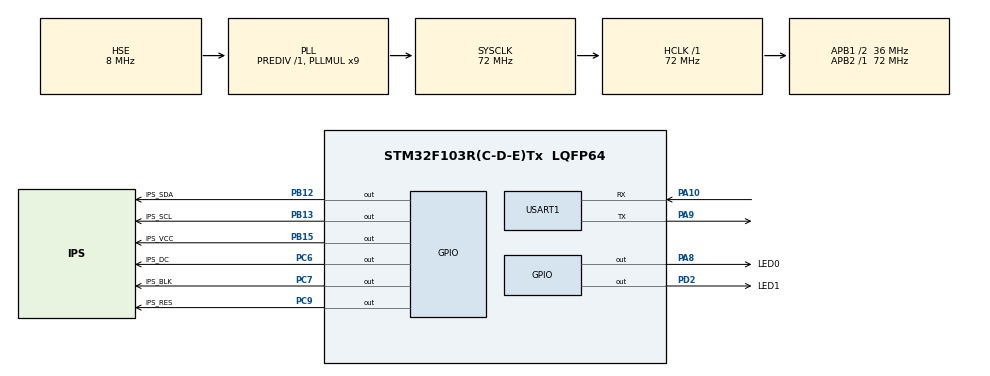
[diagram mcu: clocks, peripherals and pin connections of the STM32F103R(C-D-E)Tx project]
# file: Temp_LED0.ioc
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Mcu.Family=STM32F1
Mcu.Name=STM32F103R(C-D-E)Tx
Mcu.Package=LQFP64
NVIC.PriorityGroup=NVIC_PRIORITYGROUP_4
NVIC.USART1_IRQn=true\:2\:0\:true\:false\:true\:true\:true
PA10.Mode=Asynchronous
PA10.Signal=USART1_RX
PA13.Mode=Serial_Wire
PA13.Signal=SYS_JTMS-SWDIO
PA14.Mode=Serial_Wire
PA14.Signal=SYS_JTCK-SWCLK
PA8.GPIO_Label=LED0
PA8.GPIO_ModeDefaultOutputPP=GPIO_MODE_OUTPUT_PP
PA8.GPIO_PuPd=GPIO_PULLUP
PA8.GPIO_Speed=GPIO_SPEED_FREQ_MEDIUM
PA8.PinState=GPIO_PIN_SET
PA8.Signal=GPIO_Output
PA9.Mode=Asynchronous
PA9.Signal=USART1_TX
PB12.GPIO_Label=IPS_SDA
PB12.GPIO_ModeDefaultOutputPP=GPIO_MODE_OUTPUT_PP
PB12.GPIO_PuPd=GPIO_PULLUP
PB12.GPIO_Speed=GPIO_SPEED_FREQ_HIGH
PB12.PinState=GPIO_PIN_SET
PB12.Signal=GPIO_Output
PB13.GPIO_Label=IPS_SCL
PB13.GPIO_PuPd=GPIO_PULLUP
PB13.GPIO_Speed=GPIO_SPEED_FREQ_HIGH
PB13.PinState=GPIO_PIN_SET
PB13.Signal=GPIO_Output
PB15.GPIO_Label=IPS_VCC
PB15.GPIO_ModeDefaultOutputPP=GPIO_MODE_OUTPUT_PP
PB15.GPIO_PuPd=GPIO_PULLUP
PB15.GPIO_Speed=GPIO_SPEED_FREQ_HIGH
PB15.PinState=GPIO_PIN_SET
PB15.Signal=GPIO_Output
PC14-OSC32_IN.Mode=LSE-External-Oscillator
PC14-OSC32_IN.Signal=RCC_OSC32_IN
PC15-OSC32_OUT.Mode=LSE-External-Oscillator
PC15-OSC32_OUT.Signal=RCC_OSC32_OUT
PC6.GPIO_Label=IPS_DC
PC6.GPIO_PuPd=GPIO_PULLUP
PC6.GPIO_Speed=GPIO_SPEED_FREQ_HIGH
PC6.PinState=GPIO_PIN_SET
PC6.Signal=GPIO_Output
PC7.GPIO_Label=IPS_BLK
PC7.GPIO_ModeDefaultOutputPP=GPIO_MODE_OUTPUT_PP
PC7.GPIO_PuPd=GPIO_PULLUP
PC7.GPIO_Speed=GPIO_SPEED_FREQ_HIGH
PC7.PinState=GPIO_PIN_SET
PC7.Signal=GPIO_Output
PC9.GPIO_Label=IPS_RES
PC9.GPIO_ModeDefaultOutputPP=GPIO_MODE_OUTPUT_PP
PC9.GPIO_PuPd=GPIO_PULLUP
PC9.GPIO_Speed=GPIO_SPEED_FREQ_HIGH
PC9.PinState=GPIO_PIN_SET
PC9.Signal=GPIO_Output
PD0-OSC_IN.Mode=HSE-External-Oscillator
PD0-OSC_IN.Signal=RCC_OSC_IN
PD1-OSC_OUT.Mode=HSE-External-Oscillator
PD1-OSC_OUT.Signal=RCC_OSC_OUT
PD2.GPIO_Label=LED1
PD2.GPIO_ModeDefaultOutputPP=GPIO_MODE_OUTPUT_PP
PD2.GPIO_PuPd=GPIO_PULLUP
PD2.GPIO_Speed=GPIO_SPEED_FREQ_HIGH
PD2.PinState=GPIO_PIN_SET
PD2.Signal=GPIO_Output
ProjectManager.HeapSize=0x200
ProjectManager.StackSize=0x400
ProjectManager.TargetToolchain=MDK-ARM V5
RCC.AHBFreq_Value=72000000
RCC.APB1CLKDivider=RCC_HCLK_DIV2
RCC.APB1Freq_Value=36000000
RCC.APB1TimFreq_Value=72000000
RCC.APB2Freq_Value=72000000
RCC.APB2TimFreq_Value=72000000
RCC.HCLKFreq_Value=72000000
RCC.PLLMUL=RCC_PLL_MUL9
RCC.PLLSourceVirtual=RCC_PLLSOURCE_HSE
RCC.SYSCLKFreq_VALUE=72000000
RCC.SYSCLKSource=RCC_SYSCLKSOURCE_PLLCLK
RCC.USBFreq_Value=72000000
USART1.VirtualMode=VM_ASYNC
board=custom

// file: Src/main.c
/* USER CODE BEGIN Header */
/**
  ******************************************************************************
  * @file           : main.c
  * @brief          : Main program body
  ******************************************************************************
  * @attention
  *
  * <h2><center>&copy; Copyright (c) 2019 STMicroelectronics.
  * All rights reserved.</center></h2>
  *
  * This software component is licensed by ST under BSD 3-Clause license,
  * the "License"; You may not use this file except in compliance with the
  * License. You may obtain a copy of the License at:
  *                        opensource.org/licenses/BSD-3-Clause
  *
  ******************************************************************************
  */
/* USER CODE END Header */

#include "main.h"
#include "usart.h"
#include "gpio.h"

/* USER CODE BEGIN Includes */
#include "lcd.h"
#include "SEGGER_RTT.h"
#include "SEGGER_RTT_Conf.h"
/* USER CODE END Includes */

void SystemClock_Config(void);

int main(void)
{
  /* USER CODE BEGIN 1 */
//	uint8_t temp[] = "study cube for stm32f103 \r\n";
//	uint8_t temp_lenth = sizeof temp;

	u8 x = 0, y = 0;
  /* USER CODE END 1 */

  /* MCU Configuration--------------------------------------------------------*/

  /* Reset of all peripherals, Initializes the Flash interface and the Systick. */
  HAL_Init();

  /* USER CODE BEGIN Init */

  /* Jlink RTT Viewer 初始化 */
  SEGGER_RTT_Init();

  /* IPS屏初始化 */
  Lcd_Init();
  LCD_Clear(BLACK);
  BACK_COLOR = BLACK;

  /* USER CODE END Init */

  /* Configure the system clock */
  SystemClock_Config();

  /* Initialize all configured peripherals */
  MX_GPIO_Init();
  MX_USART1_UART_Init();

  /* Infinite loop */
  /* USER CODE BEGIN WHILE */
  while (1)
  {
	  /* IO口操作 */
// 	  HAL_GPIO_TogglePin(LED0_GPIO_Port, LED0_Pin);
// 	  HAL_GPIO_TogglePin(LED1_GPIO_Port, LED1_Pin);

	  /* 串口打印日志 */
//	  HAL_UART_Transmit(&huart1, temp, temp_lenth, 100);

	  /* IPS屏 */
	  /* 字体移动 */
// 	  for (y = 0; y < 220; y = y + 3)
// 	  {
// 		  LCD_ShowString(0, y, "Study STM32F103:", GREEN);
// 	  }
// 	  LCD_ShowString(0, 220, "                ", GREEN);

	  /*显示*/
	  /*多个终端*/
// 	  SEGGER_RTT_TerminalOut(0, "STUDY123456789\r\n");
// 	  HAL_Delay(100);
// 	  // 选择不同的终端
// 	  SEGGER_RTT_TerminalOut(1, "123456789\r\n");
// 	  HAL_Delay(100);
// 	  SEGGER_RTT_TerminalOut(2, "123456789\r\n");
// 	  HAL_Delay(100);
// 	  SEGGER_RTT_TerminalOut(3, "123456789\r\n");
// 	  HAL_Delay(100);
// 	  // 显示颜色， 颜色只能在在一个终端显示
// 	  SEGGER_RTT_WriteString(0, RTT_CTRL_RESET"GREEN: "
// 		                        RTT_CTRL_TEXT_GREEN"This text is GREEN."
// 		                        RTT_CTRL_TEXT_BLACK""
// 		                        RTT_CTRL_BG_GREEN"This background is GREEN. "
// 		                        RTT_CTRL_RESET"Normal text again.\r\n");

      SEGGER_RTT_WriteString(0, RTT_CTRL_TEXT_GREEN"GREEN: "
							    RTT_CTRL_TEXT_GREEN"study iwdg."
							    RTT_CTRL_RESET"\r\n");

	  HAL_Delay(300);

    /* USER CODE END WHILE */

  }
}

void SystemClock_Config(void)
{
  RCC_OscInitTypeDef RCC_OscInitStruct = {0};
  RCC_ClkInitTypeDef RCC_ClkInitStruct = {0};

  /** Initializes the CPU, AHB and APB busses clocks
  */
  RCC_OscInitStruct.OscillatorType = RCC_OSCILLATORTYPE_HSE;
  RCC_OscInitStruct.HSEState = RCC_HSE_ON;
  RCC_OscInitStruct.HSEPredivValue = RCC_HSE_PREDIV_DIV1;
  RCC_OscInitStruct.HSIState = RCC_HSI_ON;
  RCC_OscInitStruct.PLL.PLLState = RCC_PLL_ON;
  RCC_OscInitStruct.PLL.PLLSource = RCC_PLLSOURCE_HSE;
  RCC_OscInitStruct.PLL.PLLMUL = RCC_PLL_MUL9;
  if (HAL_RCC_OscConfig(&RCC_OscInitStruct) != HAL_OK)
  {
    Error_Handler();
  }
  /** Initializes the CPU, AHB and APB busses clocks
  */
  RCC_ClkInitStruct.ClockType = RCC_CLOCKTYPE_HCLK|RCC_CLOCKTYPE_SYSCLK
                              |RCC_CLOCKTYPE_PCLK1|RCC_CLOCKTYPE_PCLK2;
  RCC_ClkInitStruct.SYSCLKSource = RCC_SYSCLKSOURCE_PLLCLK;
  RCC_ClkInitStruct.AHBCLKDivider = RCC_SYSCLK_DIV1;
  RCC_ClkInitStruct.APB1CLKDivider = RCC_HCLK_DIV2;
  RCC_ClkInitStruct.APB2CLKDivider = RCC_HCLK_DIV1;

  if (HAL_RCC_ClockConfig(&RCC_ClkInitStruct, FLASH_LATENCY_2) != HAL_OK)
  {
    Error_Handler();
  }
}

void Error_Handler(void)
{
}

/************************ (C) COPYRIGHT STMicroelectronics *****END OF FILE****/
